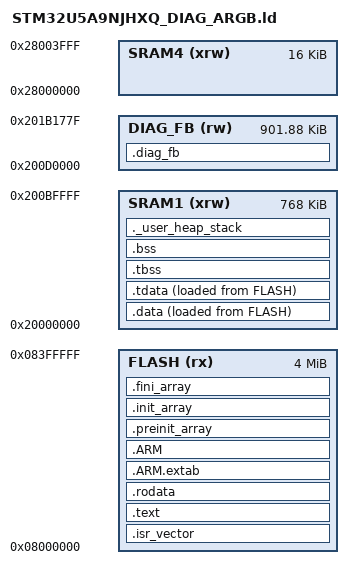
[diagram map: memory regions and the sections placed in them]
/*
******************************************************************************
**
**  File        : STM32U5A9NJHXQ_DIAG_ARGB.ld
**
**  Abstract    : M1-A diagnostic linker (docs/00_plan.md §4.4). Exclusive to
**                the M1 ARGB8888 single-buffer phase; must never coexist with
**                the formal SRAM partition layout.
**
**                Runtime (.data/.bss/stack) confined to SRAM1. The 480x481
**                ARGB8888 diagnostic framebuffer occupies exactly
**                [0x200D0000, 0x201B1780), crossing SRAM3 into SRAM5.
**
**  Target      : STMicroelectronics STM32U5A9xJ, 4096K FLASH / 2496K main SRAM
**
*****************************************************************************
*/

/* Entry Point */
ENTRY(Reset_Handler)

/* Memories definition */
MEMORY
{
  FLASH   (rx)  : ORIGIN = 0x08000000, LENGTH = 4096K
  SRAM1   (xrw) : ORIGIN = 0x20000000, LENGTH = 768K
  DIAG_FB (rw)  : ORIGIN = 0x200D0000, LENGTH = 923520 /* 480*481*4 */
  SRAM4   (xrw) : ORIGIN = 0x28000000, LENGTH = 16K
}
/* Highest address of the user mode stack */
_estack = ORIGIN(SRAM1) + LENGTH(SRAM1); /* end of "SRAM1" Ram type memory */

_Min_Heap_Size = 0x600;      /* required amount of heap  */
_Min_Stack_Size = 0x2000;    /* required amount of stack */

/* Sections */
SECTIONS
{
  /* The startup code into "FLASH" Rom type memory */
  .isr_vector :
  {
    KEEP(*(.isr_vector)) /* Startup code */
  } >FLASH

  /* The program code and other data into "FLASH" Rom type memory */
  .text :
  {
    *(.text)           /* .text sections (code) */
    *(.text*)          /* .text* sections (code) */
    *(.glue_7)         /* glue arm to thumb code */
    *(.glue_7t)        /* glue thumb to arm code */
    *(.eh_frame)

    KEEP (*(.init))
    KEEP (*(.fini))

    _etext = .;        /* define a global symbol at end of code */
  } >FLASH

  /* Constant data into "FLASH" Rom type memory */
  .rodata :
  {
    *(.rodata)         /* .rodata sections (constants, strings, etc.) */
    *(.rodata*)        /* .rodata* sections (constants, strings, etc.) */
  } >FLASH

  .ARM.extab (READONLY) : /* The READONLY keyword is only supported in GCC11 and later, remove it if using GCC10 or earlier. */
  {
    *(.ARM.extab* .gnu.linkonce.armextab.*)
  } >FLASH

  .ARM (READONLY) : /* The READONLY keyword is only supported in GCC11 and later, remove it if using GCC10 or earlier. */
  {
    __exidx_start = .;
    *(.ARM.exidx*)
    __exidx_end = .;
  } >FLASH

  .preinit_array (READONLY) :
  {
    PROVIDE_HIDDEN (__preinit_array_start = .);
    KEEP (*(.preinit_array*))
    PROVIDE_HIDDEN (__preinit_array_end = .);
  } >FLASH

  .init_array (READONLY) :
  {
    PROVIDE_HIDDEN (__init_array_start = .);
    KEEP (*(SORT(.init_array.*)))
    KEEP (*(.init_array*))
    PROVIDE_HIDDEN (__init_array_end = .);
  } >FLASH

  .fini_array (READONLY) :
  {
    PROVIDE_HIDDEN (__fini_array_start = .);
    KEEP (*(SORT(.fini_array.*)))
    KEEP (*(.fini_array*))
    PROVIDE_HIDDEN (__fini_array_end = .);
  } >FLASH

  /* Used by the startup to initialize data */
  _sidata = LOADADDR(.data);

  /* Initialized data sections into "SRAM1" Ram type memory */
  .data :
  {
    _sdata = .;        /* create a global symbol at data start */
    *(.data)           /* .data sections */
    *(.data*)          /* .data* sections */
    *(.RamFunc)        /* .RamFunc sections */
    *(.RamFunc*)       /* .RamFunc* sections */

  } >SRAM1 AT> FLASH

  /* Initialized TLS data section */
  .tdata : ALIGN(4)
  {
    *(.tdata .tdata.* .gnu.linkonce.td.*)
    . = ALIGN(4);
    _edata = .;        /* define a global symbol at data end */
    PROVIDE(__data_end = .);
    PROVIDE(__tdata_end = .);
  } >SRAM1 AT> FLASH

  PROVIDE( __tdata_start = ADDR(.tdata) );
  PROVIDE( __tdata_size = __tdata_end - __tdata_start );

  PROVIDE( __data_start = ADDR(.data) );
  PROVIDE( __data_size = __data_end - __data_start );

  PROVIDE( __tdata_source = LOADADDR(.tdata) );
  PROVIDE( __tdata_source_end = LOADADDR(.tdata) + SIZEOF(.tdata) );
  PROVIDE( __tdata_source_size = __tdata_source_end - __tdata_source );

  PROVIDE( __data_source = LOADADDR(.data) );
  PROVIDE( __data_source_end = __tdata_source_end );
  PROVIDE( __data_source_size = __data_source_end - __data_source );


  /* Uninitialized TLS data section */
  .tbss (NOLOAD) : ALIGN(4)
  {
    _sbss = .;         /* define a global symbol at bss start */
    __bss_start__ = _sbss;
    *(.tbss .tbss.*)
    . = ALIGN(4);
    PROVIDE( __tbss_end = . );
  } >SRAM1

  PROVIDE( __tbss_start = ADDR(.tbss) );
  PROVIDE( __tbss_size = __tbss_end - __tbss_start );
  PROVIDE( __tbss_offset = ADDR(.tbss) - ADDR(.tdata) );

  PROVIDE( __tls_base = __tdata_start );
  PROVIDE( __tls_end = __tbss_end );
  PROVIDE( __tls_size = __tls_end - __tls_base );
  PROVIDE( __tls_align = MAX(ALIGNOF(.tdata), ALIGNOF(.tbss)) );
  PROVIDE( __tls_size_align = (__tls_size + __tls_align - 1) & ~(__tls_align - 1) );
  PROVIDE( __arm32_tls_tcb_offset = MAX(8, __tls_align) );
  PROVIDE( __arm64_tls_tcb_offset = MAX(16, __tls_align) );

  .bss (NOLOAD) : ALIGN(4)
  {
    /* This is used by the startup in order to initialize the .bss section */
    *(.bss)
    *(.bss*)
    *(COMMON)

      . = ALIGN(4);
    _ebss = .;         /* define a global symbol at bss end */
    __bss_end__ = _ebss;
      PROVIDE( __bss_end = .);
  } >SRAM1
  PROVIDE( __non_tls_bss_start = ADDR(.bss) );

  PROVIDE( __bss_start = __tbss_start );
  PROVIDE( __bss_size = __bss_end - __bss_start );


  /* User_heap_stack section, used to check that there is enough "SRAM1" Ram type memory left */
  ._user_heap_stack (NOLOAD) :
  {
    . = ALIGN(8);
    PROVIDE ( end = . );
    PROVIDE ( _end = . );
    . = . + _Min_Heap_Size;
    . = . + _Min_Stack_Size;
    . = ALIGN(8);
  } >SRAM1

  /* M1 diagnostic framebuffer: exact 480x481x4 window, no load image */
  .diag_fb (NOLOAD) :
  {
    . = ALIGN(16);
    __diag_fb_start__ = .;
    KEEP(*(.diag_fb))
    . = ALIGN(4);
    __diag_fb_end__ = .;
  } >DIAG_FB
  ASSERT(ADDR(.diag_fb) == 0x200D0000, "diagnostic framebuffer not at 0x200D0000")
  ASSERT(SIZEOF(.diag_fb) <= 923520, "diagnostic framebuffer exceeds [0x200D0000,0x201B1780)")

  /* Remove information from the compiler libraries */
  /DISCARD/ :
  {
    libc.a:* ( * )
    libm.a:* ( * )
    libgcc.a:* ( * )
  }

  .ARM.attributes 0 : { *(.ARM.attributes) }
}
